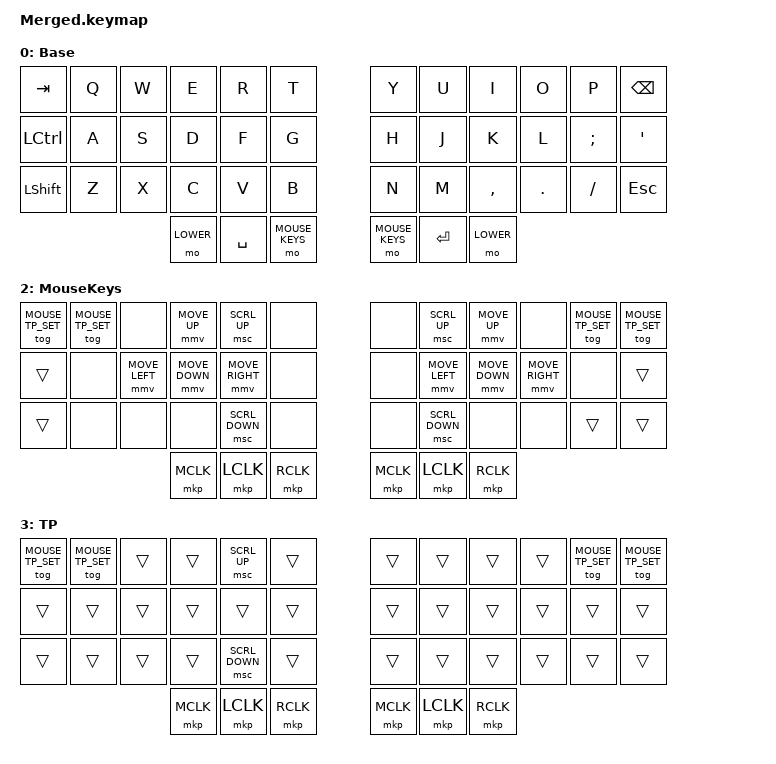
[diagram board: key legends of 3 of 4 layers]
/*
 * Copyright (c) 2020 The ZMK Contributors
 *
 * SPDX-License-Identifier: MIT
 */

#include <behaviors.dtsi>
#include <dt-bindings/zmk/keys.h>
#include <dt-bindings/zmk/bt.h>
#include <dt-bindings/zmk/outputs.h>
#include <dt-bindings/zmk/mouse.h>
#include <behaviors/mouse_keys.dtsi>

// Define feature flags
#define HAS_MOUSE_KEYS
#define HAS_MOUSE_TP

#ifdef HAS_MOUSE_TP
  #include "include/mouse_tp.dtsi"
#endif

#define BASE 0
#define LOWER 1
#define MOUSE_KEYS 2
#define MOUSE_TP 3
#define MOUSE_TP_SET 4

// Layer key defines based on features
#ifdef HAS_MOUSE_KEYS
  #define U_THUMB_INNER &mo MOUSE_KEYS
#else
  #define U_THUMB_INNER &none
#endif

#ifdef HAS_MOUSE_TP
  #define U_TOG_TP_SET &tog MOUSE_TP_SET
#else
  #define U_TOG_TP_SET &none
#endif

/ {
    combos {
        compatible = "zmk,combos";
        AdjustLayer {
            bindings = <&mo 4>;
            key-positions = <37 40>;
        };
    };

    keymap {
        compatible = "zmk,keymap";

        // Base Layer
        Base_layer {
            display-name = "Base";
            bindings = <
                &kp TAB    &kp Q    &kp W    &kp E     &kp R    &kp T        &kp Y      &kp U    &kp I      &kp O      &kp P      &kp BSPC
                &kp LCTRL  &kp A    &kp S    &kp D     &kp F    &kp G        &kp H      &kp J    &kp K      &kp L      &kp SEMI   &kp SQT
                &kp LSHFT  &kp Z    &kp X    &kp C     &kp V    &kp B        &kp N      &kp M    &kp COMMA  &kp DOT    &kp SLASH  &kp ESC
                                      &mo LOWER &kp SPACE  U_THUMB_INNER  U_THUMB_INNER &kp RET  &mo LOWER
            >;
        };

        // Lower Layer
        Lower_layer {
            display-name = "Lower";
            bindings = <
                &kp TAB  &kp N1  &kp N2  &kp N3  &kp N4  &kp N5    &kp N6  &kp N7  &kp N8  &kp N9  &kp N0  &kp BSPC
                &trans   &trans  &kp LA(LC(LEFT)) &kp LC(B) &kp LC(LA(RIGHT))  &trans  &kp LEFT  &kp DOWN &kp UP   &kp RIGHT &kp DEL &kp C_VOL_UP
                &kp LSHFT &trans  &trans  &trans  &trans  &kp F12   &kp PSCRN &kp LC(B)  &trans  &trans   &trans   &kp C_VOL_DN
                                  &kp LALT &trans  &trans  &trans   &trans  &trans  &trans
            >;
        };

#ifdef HAS_MOUSE_KEYS
        MouseKeys_layer {
            display-name = "MouseKeys";
            bindings = <
                U_TOG_TP_SET U_TOG_TP_SET &none  &mmv MOVE_UP   &msc SCRL_UP  &none   &none   &msc SCRL_UP  &mmv MOVE_UP   &none  U_TOG_TP_SET  U_TOG_TP_SET
                &trans  &none  &mmv MOVE_LEFT  &mmv MOVE_DOWN  &mmv MOVE_RIGHT  &none   &none   &mmv MOVE_LEFT  &mmv MOVE_DOWN  &mmv MOVE_RIGHT  &none  &trans
                &trans  &none  &none  &none  &msc SCRL_DOWN  &none   &none   &msc SCRL_DOWN  &none  &none  &trans  &trans
                                  &mkp MCLK  &mkp LCLK  &mkp RCLK  &mkp MCLK  &mkp LCLK  &mkp RCLK
            >;
        };
#endif

#ifdef HAS_MOUSE_TP
        MouseTP_layer {
            display-name = "TP";
            bindings = <
                U_TOG_TP_SET U_TOG_TP_SET &trans  &trans  &msc SCRL_UP  &trans   &trans   &trans  &trans  &trans  U_TOG_TP_SET  U_TOG_TP_SET
                &trans  &trans  &trans  &trans  &trans   &trans   &trans  &trans  &trans  &trans  &trans  &trans
                &trans  &trans  &trans  &trans  &msc SCRL_DOWN  &trans   &trans   &trans  &trans  &trans  &trans  &trans
                                  &mkp MCLK  &mkp LCLK  &mkp RCLK  &mkp MCLK  &mkp LCLK  &mkp RCLK
            >;
        };
#endif
    };
};
